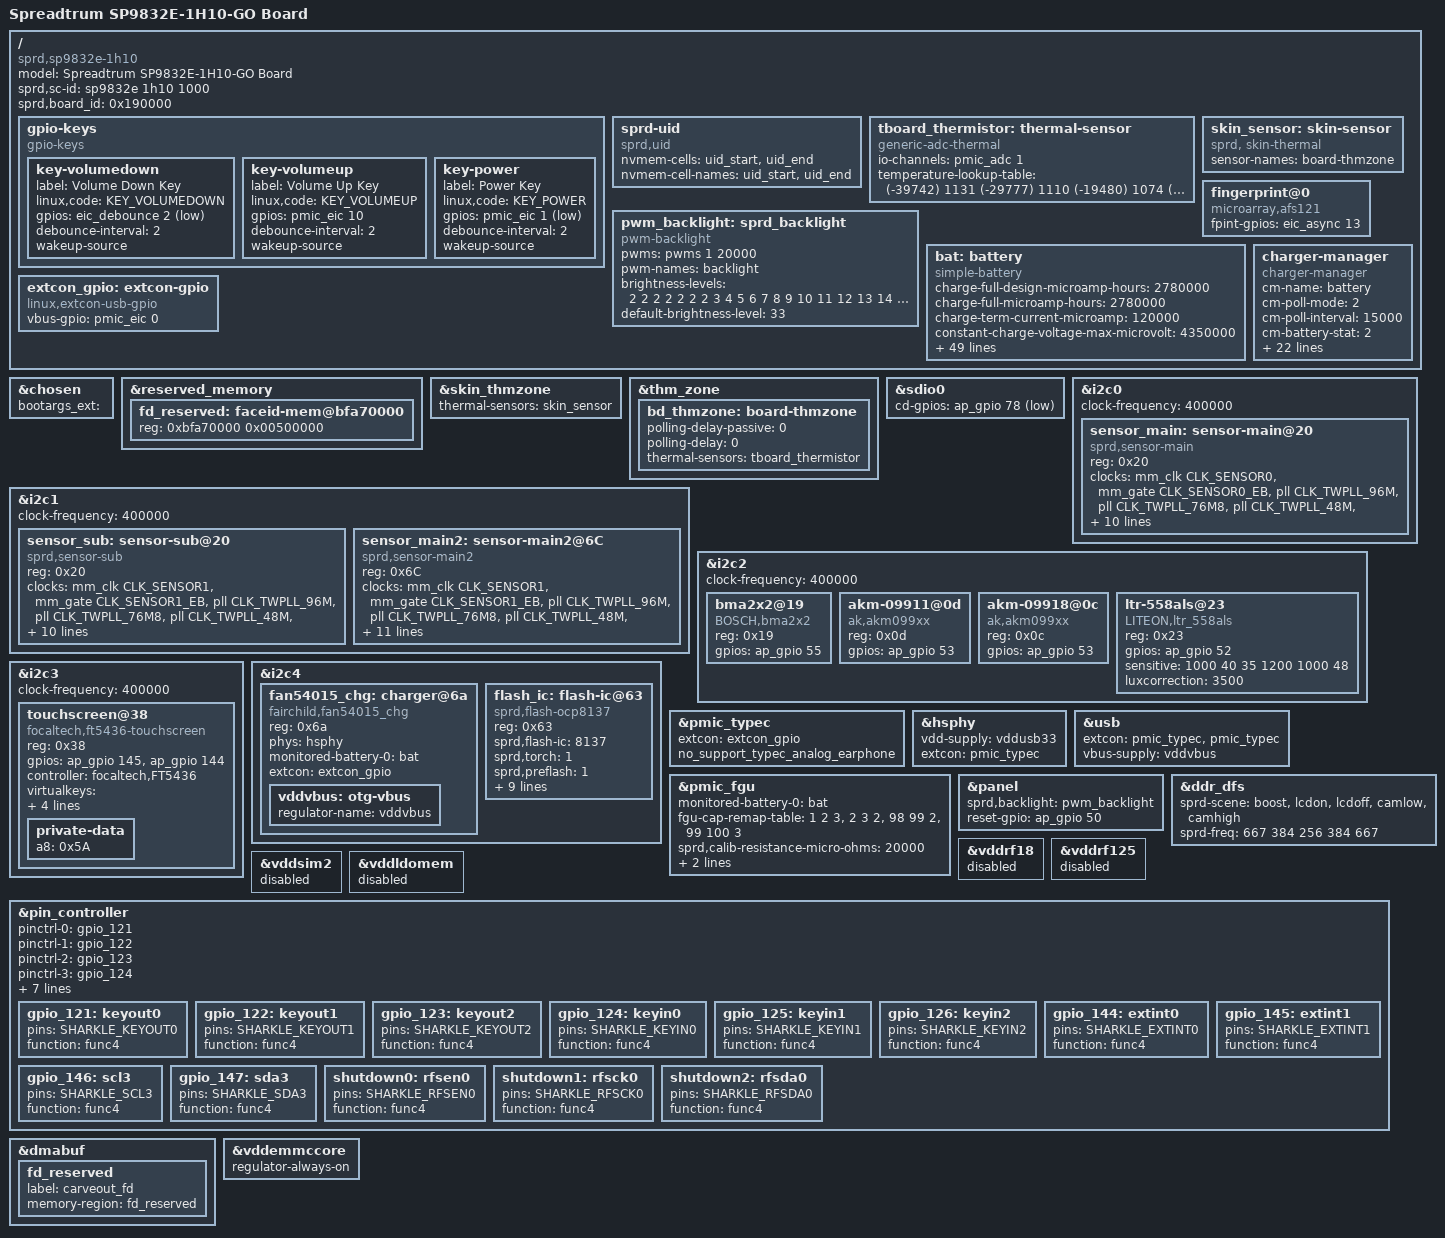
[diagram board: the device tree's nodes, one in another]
// SPDX-License-Identifier: GPL-2.0-only
/*
 * Spreadtrum sharkle sp9832e board DTS file
 *
 * Copyright (C) 2021, Spreadtrum Communications Inc.
 *
 * This file is licensed under a dual GPLv2 or X11 license.
 */
/dts-v1/;
/plugin/;
#include <dt-bindings/input/input.h>
#include <dt-bindings/gpio/gpio.h>

#include <dt-bindings/input/input.h>
#include <dt-bindings/gpio/gpio.h>
#include <dt-bindings/clock/sprd,sc9832e-clk.h>
#include "lcd/lcd_ili9881c_truly_mipi_hd.dtsi"
#include "lcd/lcd_r61350_truly_mipi_hd.dtsi"
#include "lcd/lcd_dummy_mipi.dtsi"
#include "wcn/wcn_modules.h"
#include "wcn/chip/wcn-integrate-sharkle-register.dtsi"

/ {
	model = "Spreadtrum SP9832E-1H10-GO Board";

	compatible = "sprd,sp9832e-1h10", "sprd,sc9832e";

	sprd,sc-id = "sp9832e 1h10 1000";

	sprd,board_id = <0x190000>;

	/*
	 * When create a new node, we should use the key word __overlay__,
	 * otherwise u-boot can not analyze it.
	 */
	fragment {
		target-path = "/";
		__overlay__ {
			gpio-keys {
				compatible = "gpio-keys";

				key-volumedown {
					label = "Volume Down Key";
					linux,code = <KEY_VOLUMEDOWN>;
					gpios = <&eic_debounce 2 GPIO_ACTIVE_LOW>;
					debounce-interval = <2>;
					wakeup-source;
				};

				key-volumeup {
					label = "Volume Up Key";
					linux,code = <KEY_VOLUMEUP>;
					gpios = <&pmic_eic 10 GPIO_ACTIVE_HIGH>;
					debounce-interval = <2>;
					wakeup-source;
				};

				key-power {
					label = "Power Key";
					linux,code = <KEY_POWER>;
					gpios = <&pmic_eic 1 GPIO_ACTIVE_LOW>;
					debounce-interval = <2>;
					wakeup-source;
				};
			};
			sprd-uid {
				compatible = "sprd,uid";
				nvmem-cells = <&uid_start>, <&uid_end>;
				nvmem-cell-names = "uid_start", "uid_end";
			};
			tboard_thermistor:thermal-sensor {
				compatible = "generic-adc-thermal";
				#thermal-sensor-cells = <0>;
				io-channels = <&pmic_adc 1>;
				io-channel-names = "sensor-channel";
				temperature-lookup-table = < (-39742) 1131
								(-29777) 1110
								(-19480) 1074
								(-4679) 983
								10110 838
								24805 654
								44922 413
								54903 316
								64895 238
								74884 178
								84883 133
								94883 100
								104880 75
								114889 57
								124872 43 >;
			};

			skin_sensor: skin-sensor {
				compatible = "sprd, skin-thermal";
				#thermal-sensor-cells = <0>;
				sensor-names = "board-thmzone";
			};

			fingerprint@0 {
				compatible = "microarray,afs121";
				fpint-gpios = <&eic_async 13 0>;
			};

			pwm_backlight: sprd_backlight {
				compatible = "pwm-backlight";
				pwms = <&pwms 1 20000>;
				pwm-names = "backlight";
				brightness-levels = <
								  2   2   2   2
					  2   2   2   3   4   5   6   7   8   9
					 10  11  12  13  14  15  16  17  18  19
					 20  21  22  23  24  25  26  27  28  29
					 30  31  32  33  34  35  36  37  38  39
					 40  41  42  43  44  45  46  47  48  49
					 50  51  52  53  54  55  56  57  58  59
					 60  61  62  63  64  65  66  67  68  69
					 70  71  72  73  74  75  76  77  78  79
					 80  81  82  83  84  85  86  87  88  89
					 90  91  92  93  94  95  96  97  98  99
					100 101 102 103 104 105 106 107 108 109
					110 111 112 113 114 115 116 117 118 119
					120 121 122 123 124 125 126 127 128 129
					130 131 132 133 134 135 136 137 138 139
					140 141 142 143 144 145 146 147 148 149
					150 151 152 153 154 155 156 157 158 159
					160 161 162 163 164 165 166 167 168 169
					170 171 172 173 174 175 176 177 178 179
					180 181 182 183 184 185 186 187 188 189
					190 191 192 193 194 195 196 197 198 199
					200 201 202 203 204 205 206 207 208 209
					210 211 212 213 214 215 216 217 218 219
					220 221 222 223 224 225 226 227 228 229
					230 231 232 233 234 235 236 237 238 239
					240 241 242 243 244 245 246 247 248 249
					250 251
					>;
				default-brightness-level = <33>;
			};

			bat: battery {
				compatible = "simple-battery";
				charge-full-design-microamp-hours = <2780000>;
				charge-full-microamp-hours = <2780000>;
				charge-term-current-microamp = <120000>;
				constant-charge-voltage-max-microvolt = <4350000>;
				factory-internal-resistance-micro-ohms = <320000>;
				voltage-min-design-microvolt = <3450000>;
				fullbatt-voltage = <4300000>;
				fullbatt-current = <120000>;
				fullbatt-track-end-vol = <4295000>;
				fullbatt-track-end-cur = <130000>;
				first-calib-voltage = <3630000>;
				first-calib-capacity = <40>;
				ocv-capacity-celsius = <20>;
				ocv-capacity-table-0 = <4330000 100>, <4249000 95>, <4189000 90>,
							<4133000 85>, <4081000 80>, <4034000 75>,
							<3991000 70>, <3953000 65>, <3910000 60>,
							<3866000 55>, <3836000 50>, <3813000 45>,
							<3795000 40>, <3782000 35>, <3774000 30>,
							<3765000 25>, <3750000 20>, <3726000 15>,
							<3687000 10>, <3658000 5>, <3400000 0>;
				voltage-temp-table = <1095000 800>, <986000 850>, <878000 900>,
							  <775000 950>, <678000 1000>, <590000 1050>,
							  <510000 1100>, <440000 1150>, <378000 1200>,
							  <324000 1250>, <278000 1300>, <238000 1350>,
							  <204000 1400>, <175000 1450>, <150000 1500>,
							  <129000 1550>, <111000 1600>, <96000 1650>;
				capacity-temp-table = <25 100>, <10 97>, <(-10) 60>;
				resistance-temp-table = <20 100>, <10 243>, <(-10) 468>;
				temp-advance-fullcap-table = <50 100>, <25 100>, <10 100>, <0 100>,
					<(-10) 100>, <(-20) 100>;

				charge-sdp-current-microamp = <500000 500000>;
				charge-dcp-current-microamp = <1150000 3000000>;
				charge-cdp-current-microamp = <1150000 1150000>;
				charge-unknown-current-microamp = <1050000 1050000>;

				dcp-jeita-temp-table = <1000 1030 0 4350000>,
					<1150 1180 700000 4350000>,
					<1450 1420 1150000 4350000>,
					<1600 1570 700000 4100000>;
				sdp-jeita-temp-table = <1000 1030 0 4350000>,
					<1150 1180 500000 4350000>,
					<1450 1420 500000 4350000>,
					<1600 1570 500000 4100000>;
				cdp-jeita-temp-table = <1000 1030 0 4350000>,
					<1150 1180 700000 4350000>,
					<1450 1420 1150000 4350000>,
					<1600 1570 700000 4100000>;
				unknown-jeita-temp-table = <1000 1030 0 4350000>,
					<1150 1180 700000 4350000>,
					<1450 1420 1050000 4350000>,
					<1600 1570 700000 4100000>;
			};

			charger-manager {
				compatible = "charger-manager";
				cm-name = "battery";
				cm-poll-mode = <2>;
				cm-poll-interval = <15000>;
				cm-battery-stat = <2>;

				cm-fullbatt-vchkdrop-ms = <30000>;
				cm-fullbatt-vchkdrop-volt = <60000>;
				cm-fullbatt-capacity = <100>;

				cm-battery = "battery";
				cm-chargers = "fan54015_charger";
				cm-fuel-gauge = "sc27xx-fgu";

				/* in deci centigrade */
				cm-battery-cold = <200>;
				cm-battery-cold-in-minus;
				cm-battery-hot = <800>;
				cm-battery-temp-diff = <100>;

				/* Allow charging for 6hr */
				cm-charging-max = <18000000>;
				/* recovery charging after stop charging 45min */
				cm-discharging-max = <2700000>;

				/* the interval to feed charger watchdog */
				cm-wdt-interval = <60>;

				/* drop voltage in microVolts to allow shutdown */
				cm-shutdown-voltage = <3100000>;

				/* when 99% of the time is exceeded, it will be forced to 100% */
				cm-tickle-time-out = <1500>;

				/* how much time to allow capacity change */
				cm-one-cap-time = <30>;

				/* when the safe charging voltage is exceeded, stop charging */
				cm-charge-voltage-max = <6500000>;
				/* drop voltage in microVolts to restart charging */
				cm-charge-voltage-drop = <700000>;
				cm-thermal-zone = "board-thmzone";

				phys = <&hsphy>;
				monitored-battery-0 = <&bat>;
				cm-keep-awake;
			};

			extcon_gpio: extcon-gpio {
				compatible = "linux,extcon-usb-gpio";
				vbus-gpio = <&pmic_eic 0 0>;
			};
		};
	};
};

&chosen {
	bootargs_ext = "";
};

&reserved_memory {
	#address-cells = <1>;
	#size-cells = <1>;

	fd_reserved: faceid-mem@bfa70000 {
		reg = <0xbfa70000 0x00500000>;
	};
};

&skin_thmzone {
	thermal-sensors = <&skin_sensor>;
};

&thm_zone {
	bd_thmzone: board-thmzone {
	polling-delay-passive = <0>;
	polling-delay = <0>;
	thermal-sensors = <&tboard_thermistor>;
	};
};

&sdio0 {
	cd-gpios= <&ap_gpio 78 1>;
};

&i2c0 {
	status = "okay";
	clock-frequency = <400000>;
	#address-cells = <1>;
	#size-cells = <0>;

	sensor_main: sensor-main@20 {
		compatible = "sprd,sensor-main";
		reg = <0x20>;
		clock-names = "clk_src","sensor_eb",
			"clk_96m","clk_76m8",
			"clk_48m","clk_26m";
		clocks = <&mm_clk CLK_SENSOR0>, <&mm_gate CLK_SENSOR0_EB>,
			<&pll CLK_TWPLL_96M>,<&pll CLK_TWPLL_76M8>,
			<&pll CLK_TWPLL_48M>,<&ext_26m>;
		vddio-supply = <&vddcamio>;
		vddcama-supply = <&vddcama>;
		vddcamd-supply = <&vddcamd>;
		vddcammot-supply = <&vddcammot>;
		sprd,phyid = <1>;
		csi = <&csi0>;
		power-domains = <&cam_domain>;
		reset-gpios = <&ap_gpio 44 0>;
		power-down-gpios = <&ap_gpio 46 0>;
	};
};

&i2c1 {
	status = "okay";
	clock-frequency = <400000>;
	#address-cells = <1>;
	#size-cells = <0>;

	sensor_sub: sensor-sub@20 {
		compatible = "sprd,sensor-sub";
		reg = <0x20>;
		clock-names = "clk_src","sensor_eb",
				"clk_96m","clk_76m8",
				"clk_48m","clk_26m";
		clocks = <&mm_clk CLK_SENSOR1>, <&mm_gate CLK_SENSOR1_EB>,
			<&pll CLK_TWPLL_96M>,<&pll CLK_TWPLL_76M8>,
			<&pll CLK_TWPLL_48M>,<&ext_26m>;
		vddio-supply = <&vddcamio>;
		vddcama-supply = <&vddcama>;
		vddcamd-supply = <&vddcamd>;
		vddcammot-supply = <&vddcammot>;
		sprd,phyid = <3>;
		csi = <&csi1>;
		power-domains = <&cam_domain>;
		reset-gpios = <&ap_gpio 41 0>;
		power-down-gpios = <&ap_gpio 40 0>;
	};

	sensor_main2: sensor-main2@6C {
		compatible = "sprd,sensor-main2";
		reg = <0x6C>;
		clock-names = "clk_src","sensor_eb",
				"clk_96m","clk_76m8",
				"clk_48m","clk_26m";
		clocks = <&mm_clk CLK_SENSOR1>, <&mm_gate CLK_SENSOR1_EB>,
			<&pll CLK_TWPLL_96M>,<&pll CLK_TWPLL_76M8>,
			<&pll CLK_TWPLL_48M>,<&ext_26m>;
		vddio-supply = <&vddcamio>;
		vddcama-supply = <&vddcama>;
		vddcamd-supply = <&vddcamd>;
		vddcammot-supply = <&vddcammot>;
		sprd,phyid = <2>;
		csi = <&csi1>;
		power-domains = <&cam_domain>;
		reset-gpios = <&ap_gpio 45 0>;
		power-down-gpios = <&ap_gpio 47 0>;
		dvdd-gpios = <&ap_gpio 62 0>;
	};
};

&i2c2 {
	status = "okay";
	clock-frequency = <400000>;
	#address-cells = <1>;
	#size-cells = <0>;
	bma2x2@19{
		compatible = "BOSCH,bma2x2";
		reg = <0x19>;
		gpios = <&ap_gpio 55 GPIO_ACTIVE_HIGH>;
	};

	akm-09911@0d{
		compatible = "ak,akm099xx";
		reg = <0x0d>;
		gpios = <&ap_gpio 53 GPIO_ACTIVE_HIGH>;
	};

	akm-09918@0c{
		compatible = "ak,akm099xx";
		reg = <0x0c>;
		gpios = <&ap_gpio 53 GPIO_ACTIVE_HIGH>;
	};

	ltr-558als@23{
		compatible = "LITEON,ltr_558als";
		reg = <0x23>;
		gpios = <&ap_gpio 52 GPIO_ACTIVE_HIGH>;
		sensitive = <1000 40 35 1200 1000 48>;
		luxcorrection = <3500>;
	};
};

&i2c3 {
	status = "okay";
	clock-frequency = <400000>;
	#address-cells = <1>;
	#size-cells = <0>;

	touchscreen@38 {
		compatible = "focaltech,ft5436-touchscreen";
		reg = <0x38>;
		gpios = <&ap_gpio 145 GPIO_ACTIVE_HIGH
			&ap_gpio 144 GPIO_ACTIVE_HIGH>;
		controller = "focaltech,FT5436";
		virtualkeys = <580 60 1320 60 45
				172 360 1320 60 45
				158 600 1320 60 45>;
		surface-width = <720>;
		surface-height = <1280>;
		firmware-auto-upgrade;
		private-data {
			a8 = /bits/ 8 <0x5A>;
		};
	};
};

&i2c4 {
	status = "okay";
	#address-cells = <1>;
	#size-cells = <0>;

	fan54015_chg: charger@6a {
		compatible = "fairchild,fan54015_chg";
		reg = <0x6a>;
		phys = <&hsphy>;
		monitored-battery-0 = <&bat>;
		extcon = <&extcon_gpio>;
		vddvbus:otg-vbus {
			regulator-name = "vddvbus";
		};
	};

	flash_ic: flash-ic@63 {
		compatible = "sprd,flash-ocp8137";
		reg = <0x63>;
		sprd,flash-ic = <8137>;
		sprd,torch = <1>;
		sprd,preflash = <1>;
		sprd,highlight = <1>;
		sprd,torch-level = <128>;
		sprd,preflash-level = <128>;
		sprd,highlight-level = <128>;
		sprd,lvfm-enable = <1>;
		flash-torch-en-gpios = <&ap_gpio 88 0>;
		flash-chip-en-gpios = <&ap_gpio 89 0>;
		flash-en-gpios = <&ap_gpio 76 0>;
		flash-sync-gpios = <&ap_gpio 141 0>;
	};
};

&pmic_typec {
	extcon = <&extcon_gpio>;
	no_support_typec_analog_earphone;
};

&hsphy{
	vdd-supply = <&vddusb33>;
	extcon = <&pmic_typec>;
	status = "okay";
};

&usb {
	extcon = <&pmic_typec>, <&pmic_typec>;
	vbus-supply = <&vddvbus>;
};

&pmic_fgu {
	monitored-battery-0 = <&bat>;
	fgu-cap-remap-table = <1 2 3>, <2 3 2>, <98 99 2>, <99 100 3>;
	sprd,calib-resistance-micro-ohms = <20000>;
	fgu-capacity-track;
	phys = <&hsphy>;
};

&panel {
	sprd,backlight = <&pwm_backlight>;
	reset-gpio = <&ap_gpio 50 GPIO_ACTIVE_HIGH>;
};

&ddr_dfs {
	sprd-scene = "boost", "lcdon", "lcdoff", "camlow", "camhigh";
	sprd-freq = <667 384 256 384 667>;
};

&vddrf18 {
	status = "disabled";
	};

&vddrf125 {
		status = "disabled";
	};

&vddsim2 {
		status = "disabled";
	};

&vddldomem {
		status = "disabled";
	};

&pin_controller {
	pinctrl-names =
	/* keyout0 ~ keyout2 */
	"gpio_121", "gpio_122", "gpio_123",
	/* keyin0 ~ keyin2 */
	"gpio_124", "gpio_125", "gpio_126",
	/* extint0, extint1, scl3, sda3 */
	"gpio_144", "gpio_145", "gpio_146", "gpio_147",
	/* Note:If create a new board,need to add the shutdown node */
	"shutdown";
	pinctrl-0 = <&gpio_121>;
	pinctrl-1 = <&gpio_122>;
	pinctrl-2 = <&gpio_123>;
	pinctrl-3 = <&gpio_124>;
	pinctrl-4 = <&gpio_125>;
	pinctrl-5 = <&gpio_126>;
	pinctrl-6 = <&gpio_144>;
	pinctrl-7 = <&gpio_145>;
	pinctrl-8 = <&gpio_146>;
	pinctrl-9 = <&gpio_147>;
	pinctrl-10 = <&shutdown0
			&shutdown1
			&shutdown2>;

	gpio_121: keyout0 {
		pins = "SHARKLE_KEYOUT0";
		function = "func4";
	};

	gpio_122: keyout1 {
		pins = "SHARKLE_KEYOUT1";
		function = "func4";
	};

	gpio_123: keyout2 {
		pins = "SHARKLE_KEYOUT2";
		function = "func4";
	};

	gpio_124: keyin0 {
		pins = "SHARKLE_KEYIN0";
		function = "func4";
	};

	gpio_125: keyin1 {
		pins = "SHARKLE_KEYIN1";
		function = "func4";
	};

	gpio_126: keyin2 {
		pins = "SHARKLE_KEYIN2";
		function = "func4";
	};

	gpio_144: extint0 {
		pins = "SHARKLE_EXTINT0";
		function = "func4";
	};

	gpio_145: extint1 {
		pins = "SHARKLE_EXTINT1";
		function = "func4";
	};

	gpio_146: scl3 {
		pins = "SHARKLE_SCL3";
		function = "func4";
	};

	gpio_147: sda3 {
		pins = "SHARKLE_SDA3";
		function = "func4";
	};

	shutdown0: rfsen0 {
		pins = "SHARKLE_RFSEN0";
		function = "func4";
	};

	shutdown1: rfsck0 {
		pins = "SHARKLE_RFSCK0";
		function = "func4";
	};

	shutdown2: rfsda0 {
		pins = "SHARKLE_RFSDA0";
		function = "func4";
	};
};

&dmabuf {
	fd_reserved {
		label = "carveout_fd";
		memory-region = <&fd_reserved>;
	};
};

&vddemmccore {
	regulator-always-on;
};
